# RL6678_IP_SVD register map
Vendor: Realtek
Registers are 32-bit, read-write, reset 0x0 unless marked. A register's access mark holds for its fields unless they carry their own. Offsets are from the block's base; [hi:lo] are bit positions; {n}, {i} and the like mark numbered series.

## HP_SYS
Base 0x41000000
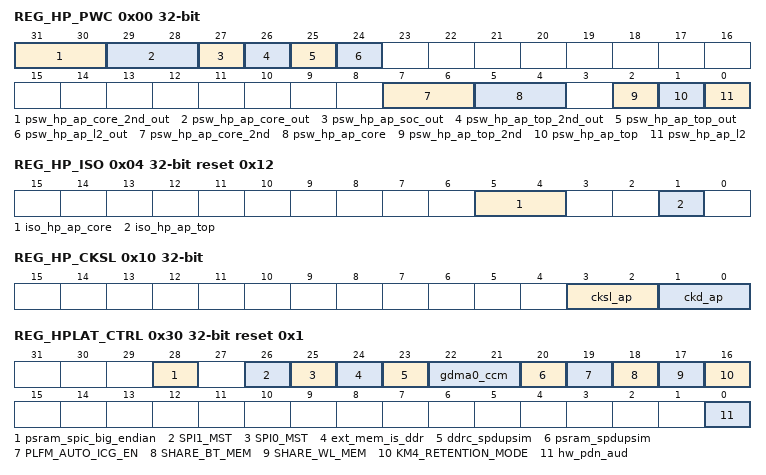
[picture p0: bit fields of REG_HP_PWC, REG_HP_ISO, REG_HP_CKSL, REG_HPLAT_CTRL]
0x00 REG_HP_PWC access per field
  [31:30] psw_hp_ap_core_2nd_out ro — AP macro core power domain 2nd switch state, active 1 [0]: core0 [1]: core1
  [29:28] psw_hp_ap_core_out ro — AP macro core power domain switch state,active 1 [0]: core0 [1]: core1
  [27] psw_hp_ap_soc_out ro — SOC AP top power domain switch state,active 1
  [26] psw_hp_ap_top_2nd_out ro — AP macro top power domain 2nd switch state
  [25] psw_hp_ap_top_out ro — AP macro top power domain switch state,active 1
  [24] psw_hp_ap_l2_out ro — AP macro L2 power domain switch state,active 1
  [7:6] psw_hp_ap_core_2nd rw — AP macro core power domain 2nd switch enable,active 1 [0]: core0 [1]: core1
  [5:4] psw_hp_ap_core rw — AP macro core power domain switch enable,active 1 [0]: core0 [1]: core1
  [2] psw_hp_ap_top_2nd rw — AP macro top power domain 2nd switch enable,active 1
  [1] psw_hp_ap_top rw — AP macro top power domain switch enable,active 1
  [0] psw_hp_ap_l2 rw — AP macro L2 power domain switch enable,active 1
0x04 REG_HP_ISO reset 0x12
  [5:4] iso_hp_ap_core — AP macro core power domain isolatation, 1: isolation [0]: core0 [1]: core1
  [1] iso_hp_ap_top — AP macro top power domain isolatation, 1: isolation
0x08 REG_HP_FEN
  [0] fen_ap — CA7 function enable
0x0C REG_HP_CKE
  [0] cke_ap — CA7 clock enable .
0x10 REG_HP_CKSL
  [3:2] cksl_ap — CA7 clock selection 00: ap pll out (1.2G default) 10: ap pll div2 out (1.2G/2) 01/11: np pll out (600M)
  [1:0] ckd_ap — CA7 clock divider , this is after clk select by cksl_ap 00: div1 01: div2 10: div3 11: div4
0x30 REG_HPLAT_CTRL reset 0x1
  [28] psram_spic_big_endian — 1: big endian 0: little endian
  [26] SPI1_MST — 1: SPI1 used as master 0: SPI1 used as slaver
  [25] SPI0_MST — 1: SPI0 used as master 0: SPI0 used as slaver
  [24] ext_mem_is_ddr — system DDR PSRAM select 1: using DDR 0: using PSRAM
  [23] ddrc_spdupsim — ddrc simulatin speedup enable
  [22:21] gdma0_ccm — GDMA0 clock control mode
  [20] psram_spdupsim — psramc simulatin speedup enable
  [19] PLFM_AUTO_ICG_EN — 1: Enable HS platform auto clock-gating for power saving 0: Disable
  [18] SHARE_BT_MEM — 1: Enable KM4 to share BT memory
  [17] SHARE_WL_MEM — 1: Enable KM4 to share WL memory
  [16] KM4_RETENTION_MODE — 1: Enable, when KM4 reset, cache will not be cleared 0: Disable, when KM4 reset, cache will be cleared by HW
  [0] hw_pdn_aud — After enable audio swr , then this bit set to 1 . Before shutdown audio swr , this bit must set to 0 . Default 1 for old project .
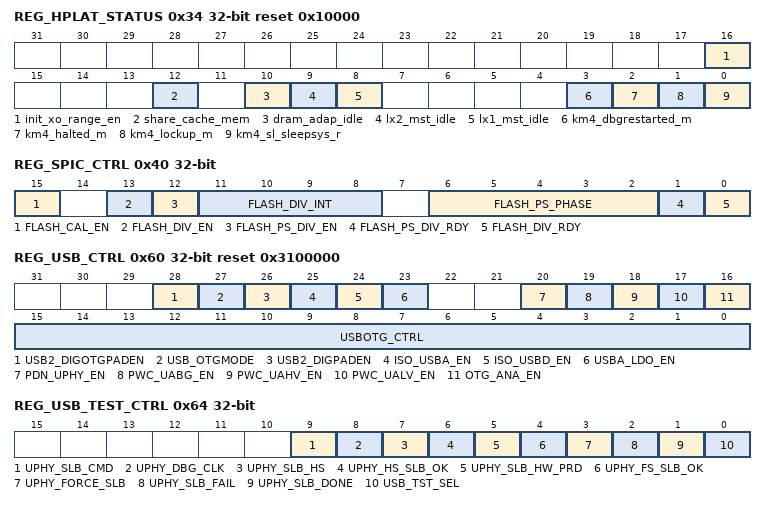
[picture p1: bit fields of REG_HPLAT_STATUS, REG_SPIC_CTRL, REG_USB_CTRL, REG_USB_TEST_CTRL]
0x34 REG_HPLAT_STATUS access per field reset 0x10000
  [16] init_xo_range_en rw
  [12] share_cache_mem rw — global control for cache shared with dtcm0 0: share disable 1: global share enable , to share cache more flex , it need control icrr and dcrr reg in cpu
  [10] dram_adap_idle ro
  [9] lx2_mst_idle ro — Indicate Lx2 mst is idle
  [8] lx1_mst_idle ro — Indicate Lx1 mst is idle
  [3] km4_dbgrestarted_m ro — KM4 debug restart status
  [2] km4_halted_m ro — KM4 halt status
  [1] km4_lockup_m ro — KM4 lockup status
  [0] km4_sl_sleepsys_r ro — KM4 sleep status
0x38 REG_KM4_XO_CTRL0 reset 0x140
  [31:0] init_xo_base
0x3C REG_KM4_XO_CTRL1 reset 0x98E0
  [31:0] init_xo_top
0x40 REG_SPIC_CTRL access per field
  [15] FLASH_CAL_EN rw — Flash calibration enable 1: delay flash sout for calibration 0: bypass flash sout to spic
  [13] FLASH_DIV_EN rw — 1: enable to generate flash clock (no phase shift) divided by 600M pll clock, HW detect this signal's rising edge to start the no phase shift division circuit.
  [12] FLASH_PS_DIV_EN rw — 1: enable to generate flash clock (with phase shift) divided by 600M pll clock, HW detect this signal's rising edge to start the phase shift clock division circuit.
  [11:8] FLASH_DIV_INT rw — Flash clock division ratio, integrate part 0: not support 1: divided by 2 2: divided by 3 3: divided by 4 .. 7: divided by 8 8: divided by 9 9: divided by 10 Note: SPI clock frequency is this divided clock/2
  [6:2] FLASH_PS_PHASE rw — Flash clock phase shift in units of 1/2 np PLL clock cycles. If np PLL is 1GHz, the step is 0.5ns. 0: shift 0 step 1: shift 1 step ... 19: shift 19 step. Note, this value cannot be set more than (FLASH_DIV_INT+1) * 2-1, for example, if DIV_INT is 1 , which means spic clock is 1/2 NPPLL , then the most shift step setting is 3, which is 4 step can be used.
  [1] FLASH_PS_DIV_RDY ro — Ready flag of Flash clock with phase shift, Read only (input signal)
  [0] FLASH_DIV_RDY ro — Ready flag of Flash clock, Read only (input signal)
0x60 REG_USB_CTRL reset 0x3100000
  [28] USB2_DIGOTGPADEN
  [27] USB_OTGMODE
  [26] USB2_DIGPADEN
  [25] ISO_USBA_EN — 1: Enable signal from uSBPHY analog 0: disable
  [24] ISO_USBD_EN
  [23] USBA_LDO_EN
  [20] PDN_UPHY_EN — 0: enable USBPHY shutdown
  [19] PWC_UABG_EN — 1: enable USBPHY BG power cut
  [18] PWC_UAHV_EN — 1: enable USBPHY HV power cut
  [17] PWC_UALV_EN — 1: enable USBPHY LV power cut
  [16] OTG_ANA_EN — 1: enable usb aphy lv2hv, hv2lv check for otg
  [15:0] USBOTG_CTRL
0x64 REG_USB_TEST_CTRL access per field
  [9] UPHY_SLB_CMD rw
  [8] UPHY_DBG_CLK ro
  [7] UPHY_SLB_HS rw
  [6] UPHY_HS_SLB_OK ro
  [5] UPHY_SLB_HW_PRD ro
  [4] UPHY_FS_SLB_OK ro
  [3] UPHY_FORCE_SLB rw
  [2] UPHY_SLB_FAIL ro
  [1] UPHY_SLB_DONE ro
  [0] USB_TST_SEL rw — select the location where the USB test signals are from 0: register 1: PINMUX GPIO
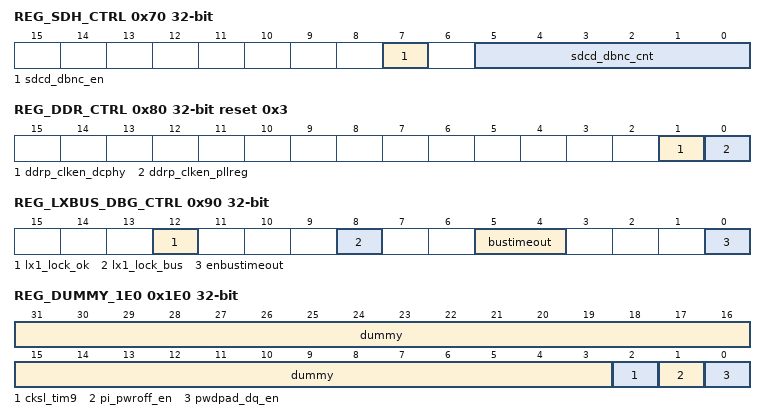
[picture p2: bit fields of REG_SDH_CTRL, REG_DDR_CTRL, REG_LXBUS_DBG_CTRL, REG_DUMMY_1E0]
0x70 REG_SDH_CTRL
  [7] sdcd_dbnc_en — 1: enable SDH card connect debounce
  [5:0] sdcd_dbnc_cnt — debounce count value, unit is 1ms
0x80 REG_DDR_CTRL reset 0x3
  [1] ddrp_clken_dcphy — 1: enable all rbus signal 0: disable all rbus clock signal
  [0] ddrp_clken_pllreg — 1: enable ddr phy crt register rbus clock 0: disable
0x90 REG_LXBUS_DBG_CTRL access per field
  [12] lx1_lock_ok ro — lock lx1 bus lock ok
  [8] lx1_lock_bus rw — lock lx1 bus for debug
  [5:4] bustimeout rw — lx sys bus arb timeout thresh
  [0] enbustimeout rw — lx sys bus arb timeout enable
0x94 REG_LXBUS_DBG0 ro
  [31:0] timeout_addr_mst — lx sys bus addr debug out
0x98 REG_LXBUS_DBG1 ro
  [31:0] timeout_addr_slv — lx sys bus addr debug out
{0x180+4i} REG_RSVD_FOR_SW{i} (i=0..3)
  [31:0] dummy — HW used only , these are for reserved.
0x1E0 REG_DUMMY_1E0
  [31:3] dummy — HW used only , these are for reserved.
  [2] cksl_tim9 — select tim9 clock source 0: xtal 40M 1: i2s 45M/2
  [1] pi_pwroff_en — ECO: enable to shutdown ddrphy PI + dq pads after entering self-refresh state, only for ddr
  [0] pwdpad_dq_en — ECO: enable to shutdown dq pads when idle, for both ddr and psram must be set after configuring pwdpad_idle_val Note: only stop psram auto axi access, manually enable/disable this bit when using psram user axi access
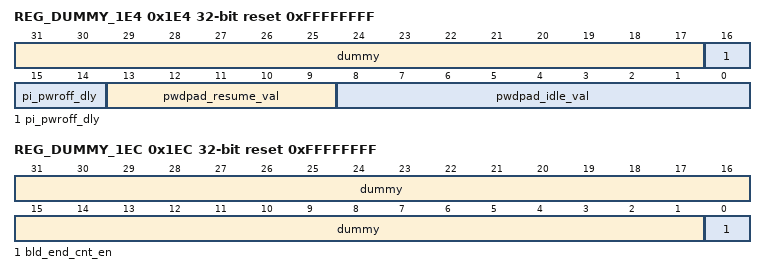
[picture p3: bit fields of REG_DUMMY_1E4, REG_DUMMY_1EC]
0x1E4 REG_DUMMY_1E4 reset 0xFFFFFFFF
  [31:17] dummy — HW used only , these are for reserved.
  [16:14] pi_pwroff_dly — ECO: after shutdown ddrphy CK_OE, delay several cycles(4T~8T dfi_clk) to shutdown ddrphy PI
  [13:9] pwdpad_resume_val — ECO: dq pads resume counter setting, only for psram, auto axi access will be stopped until resume done
  [8:0] pwdpad_idle_val — ECO: idle counter setting, only for psram, shutdown dq pads after reaching this value
0x1E8 REG_DUMMY_1E8
  [31:0] dummy — HW used only , these are for reserved.
0x1EC REG_DUMMY_1EC reset 0xFFFFFFFF
  [31:1] dummy — HW used only , these are for reserved.
  [0] bld_end_cnt_en — ECO:LCDC bld_end cnt enable
0x1F0 REG_BOUNDARY_CHK reset 0xBDC20512
  [31:0] dummy — Used for access boundary check, SYSON is 512B which is 000-1FF.
0x1F4 REG_DUMMY_1F4
  [31:0] dummy — HW used only , these are for reserved.
0x1F8 REG_DUMMY_1F8 reset 0xFFFFFFFF
  [31:0] dummy — HW used only , these are for reserved.
0x1FC REG_DUMMY_1FC
  [31:0] dummy — HW used only , these are for reserved.
